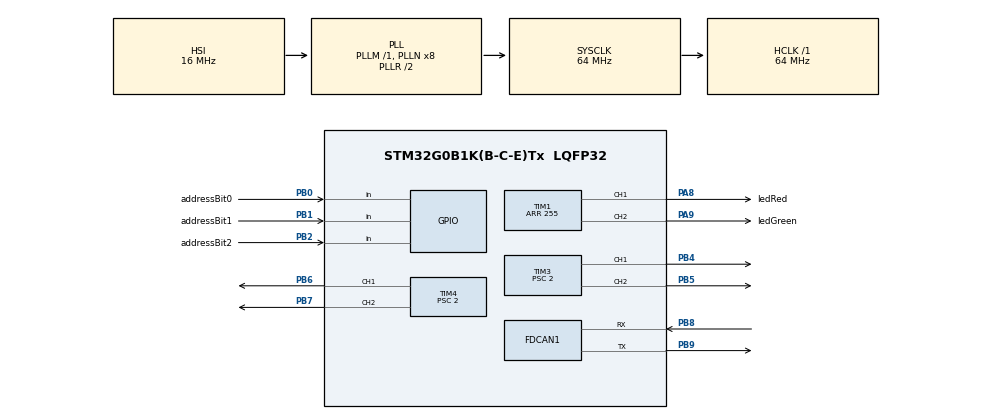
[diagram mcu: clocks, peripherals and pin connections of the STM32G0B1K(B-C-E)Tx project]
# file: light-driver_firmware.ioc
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FDCAN1.CalculateBaudRateNominal=80000
FDCAN1.CalculateTimeBitNominal=12500
FDCAN1.CalculateTimeQuantumNominal=3125.0
FDCAN1.ClockDivider=FDCAN_CLOCK_DIV10
FDCAN1.NominalPrescaler=20
FDCAN1.NominalTimeSeg1=1
FDCAN1.NominalTimeSeg2=2
FREERTOS.Tasks01=defaultTask,24,256,StartDefaultTask,As weak,NULL,Dynamic,NULL,NULL
FREERTOS.configCHECK_FOR_STACK_OVERFLOW=2
FREERTOS.configRECORD_STACK_HIGH_ADDRESS=1
FREERTOS.configTOTAL_HEAP_SIZE=15000
Mcu.Family=STM32G0
Mcu.Name=STM32G0B1K(B-C-E)Tx
Mcu.Package=LQFP32
NVIC.TIM16_FDCAN_IT0_IRQn=true\:3\:0\:false\:false\:true\:true\:true\:true\:true
NVIC.TIM6_DAC_LPTIM1_IRQn=true\:3\:0\:false\:false\:true\:false\:false\:true\:true
NVIC.TimeBase=TIM6_DAC_LPTIM1_IRQn
NVIC.TimeBaseIP=TIM6
PA12\ [PA10].Signal=SPI1_MOSI
PA13.Mode=Serial_Wire
PA13.Signal=SYS_SWDIO
PA14-BOOT0.Mode=Serial_Wire
PA14-BOOT0.Signal=SYS_SWCLK
PA8.GPIO_Label=ledRed
PA8.Signal=S_TIM1_CH1
PA9.GPIO_Label=ledGreen
PA9.Signal=S_TIM1_CH2
PB0.GPIO_Label=addressBit0
PB0.GPIO_PuPd=GPIO_PULLDOWN
PB0.Signal=GPIO_Input
PB1.GPIO_Label=addressBit1
PB1.GPIO_PuPd=GPIO_PULLDOWN
PB1.Signal=GPIO_Input
PB2.GPIO_Label=addressBit2
PB2.GPIO_PuPd=GPIO_PULLDOWN
PB2.Signal=GPIO_Input
PB3.Signal=SPI1_SCK
PB4.Signal=S_TIM3_CH1
PB5.Signal=S_TIM3_CH2
PB6.Signal=S_TIM4_CH1
PB7.Signal=S_TIM4_CH2
PB8.GPIO_PuPd=GPIO_PULLUP
PB8.Mode=FDCAN_Activate
PB8.Signal=FDCAN1_RX
PB9.Mode=FDCAN_Activate
PB9.Signal=FDCAN1_TX
ProjectManager.HeapSize=0x200
ProjectManager.StackSize=0x400
ProjectManager.TargetToolchain=CMake
RCC.ADCFreq_Value=64000000
RCC.AHBFreq_Value=64000000
RCC.CortexFreq_Value=64000000
RCC.EXTERNAL_CLOCK_VALUE=48000
RCC.HCLKFreq_Value=64000000
RCC.HSE_VALUE=8000000
RCC.HSI48_VALUE=48000000
RCC.HSI_VALUE=16000000
RCC.LSE_VALUE=32768
RCC.SYSCLKFreq_VALUE=64000000
RCC.SYSCLKSource=RCC_SYSCLKSOURCE_PLLCLK
RCC.USBFreq_Value=48000000
RCC.VCOOutputFreq_Value=128000000
SH.S_TIM1_CH1.0=TIM1_CH1,PWM Generation1 CH1
SH.S_TIM1_CH2.0=TIM1_CH2,PWM Generation2 CH2
SH.S_TIM3_CH1.0=TIM3_CH1,PWM Generation1 CH1
SH.S_TIM3_CH2.0=TIM3_CH2,PWM Generation2 CH2
SH.S_TIM4_CH1.0=TIM4_CH1,PWM Generation1 CH1
SH.S_TIM4_CH2.0=TIM4_CH2,PWM Generation2 CH2
TIM1.Channel-PWM\ Generation1\ CH1=TIM_CHANNEL_1
TIM1.Channel-PWM\ Generation2\ CH2=TIM_CHANNEL_2
TIM1.ClockDivision=TIM_CLOCKDIVISION_DIV4
TIM1.Period=255
TIM3.Channel-PWM\ Generation1\ CH1=TIM_CHANNEL_1
TIM3.Channel-PWM\ Generation2\ CH2=TIM_CHANNEL_2
TIM3.Period=1023
TIM3.Prescaler=2
TIM4.Channel-PWM\ Generation1\ CH1=TIM_CHANNEL_1
TIM4.Channel-PWM\ Generation2\ CH2=TIM_CHANNEL_2
TIM4.Period=1023
TIM4.Prescaler=2
VP_FREERTOS_VS_CMSIS_V2.Mode=CMSIS_V2
VP_SYS_VS_DBSignals.Mode=DisableDeadBatterySignals
VP_SYS_VS_tim6.Mode=TIM6
VP_TIM1_VS_ClockSourceINT.Mode=Internal
board=custom

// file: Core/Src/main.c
/* USER CODE BEGIN Header */
/**
  ******************************************************************************
  * @file           : main.c
  * @brief          : Main program body
  ******************************************************************************
  * @attention
  *
  * Copyright (c) 2025 STMicroelectronics.
  * All rights reserved.
  *
  * This software is licensed under terms that can be found in the LICENSE file
  * in the root directory of this software component.
  * If no LICENSE file comes with this software, it is provided AS-IS.
  *
  ******************************************************************************
  */
/* USER CODE END Header */
#include "main.h"
#include "cmsis_os.h"
#include "fdcan.h"
#include "tim.h"
#include "gpio.h"

void SystemClock_Config(void);
void MX_FREERTOS_Init(void);

int main(void)
{

  /* MCU Configuration--------------------------------------------------------*/

  /* Reset of all peripherals, Initializes the Flash interface and the Systick. */
  HAL_Init();

  /* Configure the system clock */
  SystemClock_Config();

  /* Initialize all configured peripherals */
  MX_GPIO_Init();
  MX_FDCAN1_Init();
  MX_TIM3_Init();
  MX_TIM4_Init();
  MX_TIM1_Init();

  /* Init scheduler */
  osKernelInitialize();  /* Call init function for freertos objects (in cmsis_os2.c) */
  MX_FREERTOS_Init();

  /* Start scheduler */
  osKernelStart();

  /* We should never get here as control is now taken by the scheduler */

  /* Infinite loop */
  while (1)
  {

  }
}

void SystemClock_Config(void)
{
  RCC_OscInitTypeDef RCC_OscInitStruct = {0};
  RCC_ClkInitTypeDef RCC_ClkInitStruct = {0};

  /** Configure the main internal regulator output voltage
  */
  HAL_PWREx_ControlVoltageScaling(PWR_REGULATOR_VOLTAGE_SCALE1);

  /** Initializes the RCC Oscillators according to the specified parameters
  * in the RCC_OscInitTypeDef structure.
  */
  RCC_OscInitStruct.OscillatorType = RCC_OSCILLATORTYPE_HSI;
  RCC_OscInitStruct.HSIState = RCC_HSI_ON;
  RCC_OscInitStruct.HSIDiv = RCC_HSI_DIV1;
  RCC_OscInitStruct.HSICalibrationValue = RCC_HSICALIBRATION_DEFAULT;
  RCC_OscInitStruct.PLL.PLLState = RCC_PLL_ON;
  RCC_OscInitStruct.PLL.PLLSource = RCC_PLLSOURCE_HSI;
  RCC_OscInitStruct.PLL.PLLM = RCC_PLLM_DIV1;
  RCC_OscInitStruct.PLL.PLLN = 8;
  RCC_OscInitStruct.PLL.PLLP = RCC_PLLP_DIV2;
  RCC_OscInitStruct.PLL.PLLQ = RCC_PLLQ_DIV2;
  RCC_OscInitStruct.PLL.PLLR = RCC_PLLR_DIV2;
  if (HAL_RCC_OscConfig(&RCC_OscInitStruct) != HAL_OK)
  {
    Error_Handler();
  }

  /** Initializes the CPU, AHB and APB buses clocks
  */
  RCC_ClkInitStruct.ClockType = RCC_CLOCKTYPE_HCLK|RCC_CLOCKTYPE_SYSCLK
                              |RCC_CLOCKTYPE_PCLK1;
  RCC_ClkInitStruct.SYSCLKSource = RCC_SYSCLKSOURCE_PLLCLK;
  RCC_ClkInitStruct.AHBCLKDivider = RCC_SYSCLK_DIV1;
  RCC_ClkInitStruct.APB1CLKDivider = RCC_HCLK_DIV1;

  if (HAL_RCC_ClockConfig(&RCC_ClkInitStruct, FLASH_LATENCY_2) != HAL_OK)
  {
    Error_Handler();
  }
}

void HAL_TIM_PeriodElapsedCallback(TIM_HandleTypeDef *htim)
{
  if (htim->Instance == TIM6)
  {
    HAL_IncTick();
  }
}

void Error_Handler(void)
{
  __disable_irq();
  while (1)
  {
  }
}

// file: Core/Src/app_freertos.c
/* USER CODE BEGIN Header */
/**
  ******************************************************************************
  * File Name          : app_freertos.c
  * Description        : Code for freertos applications
  ******************************************************************************
  * @attention
  *
  * Copyright (c) 2025 STMicroelectronics.
  * All rights reserved.
  *
  * This software is licensed under terms that can be found in the LICENSE file
  * in the root directory of this software component.
  * If no LICENSE file comes with this software, it is provided AS-IS.
  *
  ******************************************************************************
  */
/* USER CODE END Header */

#include "FreeRTOS.h"
#include "task.h"
#include "main.h"
#include "cmsis_os.h"

/* USER CODE BEGIN Includes */
#include "core/fault_handler.h"
/* USER CODE END Includes */

/* Definitions for defaultTask */
osThreadId_t defaultTaskHandle;
const osThreadAttr_t defaultTask_attributes = {
  .name = "defaultTask",
  .priority = (osPriority_t) osPriorityNormal,
  .stack_size = 256 * 4
};

void StartDefaultTask(void *argument);

void MX_FREERTOS_Init(void); /* (MISRA C 2004 rule 8.1) */

/* Hook prototypes */
void vApplicationStackOverflowHook(xTaskHandle xTask, signed char *pcTaskName);

/* USER CODE BEGIN 4 */
void vApplicationStackOverflowHook(xTaskHandle xTask, signed char *pcTaskName)
{
   faultHandler();
   /* Run time stack overflow checking is performed if
   configCHECK_FOR_STACK_OVERFLOW is defined to 1 or 2. This hook function is
   called if a stack overflow is detected. */
}
/* USER CODE END 4 */

void MX_FREERTOS_Init(void) {

  /* Create the thread(s) */
  /* creation of defaultTask */
  defaultTaskHandle = osThreadNew(StartDefaultTask, NULL, &defaultTask_attributes);

}

__weak void StartDefaultTask(void *argument)
{
  for(;;)
  {
    osDelay(1);
  }
}
